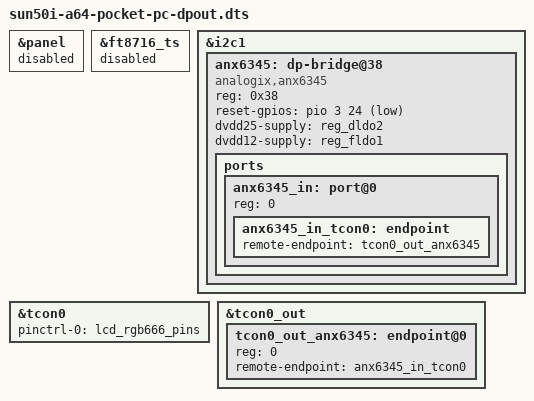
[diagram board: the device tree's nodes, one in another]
#include "sun50i-a64-pocket-pc.dts"

&panel {
	status = "disabled";
};

&ft8716_ts {
	status = "disabled";
};

&i2c1 {
	anx6345: dp-bridge@38 {
		compatible = "analogix,anx6345";
		reg = <0x38>;
		reset-gpios = <&pio 3 24 GPIO_ACTIVE_LOW>; /* PD24 */
		dvdd25-supply = <&reg_dldo2>;
		dvdd12-supply = <&reg_fldo1>;

		ports {
			#address-cells = <1>;
			#size-cells = <0>;

			anx6345_in: port@0 {
				reg = <0>;
				anx6345_in_tcon0: endpoint {
					remote-endpoint = <&tcon0_out_anx6345>;
				};
			};
		};
	};
};

&tcon0 {
	pinctrl-names = "default";
	pinctrl-0 = <&lcd_rgb666_pins>;

	status = "okay";
};

&tcon0_out {
	tcon0_out_anx6345: endpoint@0 {
		reg = <0>;
		remote-endpoint = <&anx6345_in_tcon0>;
	};
};
